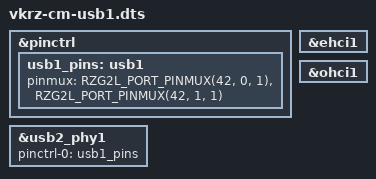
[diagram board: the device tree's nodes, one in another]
/*
 * Copyright 2024 Vekatech
 *
 * This program is free software; you can redistribute it and/or
 * modify it under the terms of the GNU General Public License
 * as published by the Free Software Foundation; either version 2
 * of the License, or (at your option) any later version.
 *
 * This program is distributed in the hope that it will be useful,
 * but WITHOUT ANY WARRANTY; without even the implied warranty of
 * MERCHANTABILITY or FITNESS FOR A PARTICULAR PURPOSE. See the
 * GNU General Public License for more details.
 */

/dts-v1/;
/plugin/;

#include <dt-bindings/pinctrl/rzg2l-pinctrl.h>


&pinctrl {
	usb1_pins: usb1 {
		pinmux = <RZG2L_PORT_PINMUX(42, 0, 1)>, /* VBUS */
			 <RZG2L_PORT_PINMUX(42, 1, 1)>; /* OVC */
	};
};

&usb2_phy1 {
	pinctrl-0 = <&usb1_pins>;
	pinctrl-names = "default";

	status = "okay";
};

&ehci1 {
	status = "okay";
};

&ohci1 {
	status = "okay";
};
